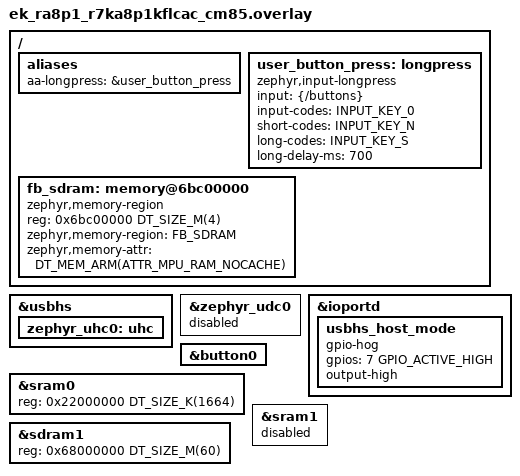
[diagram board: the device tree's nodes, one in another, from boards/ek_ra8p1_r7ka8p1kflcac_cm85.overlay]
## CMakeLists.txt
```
# Copyright The Zephyr Project Contributors
# SPDX-License-Identifier: Apache-2.0

cmake_minimum_required(VERSION 3.28.0)
find_package(Zephyr REQUIRED HINTS $ENV{ZEPHYR_BASE})
project(android_auto_headunit)

list(APPEND CMAKE_MODULE_PATH ${ZEPHYR_BASE}/modules/nanopb)
include(nanopb)

zephyr_nanopb_sources(app src/aa.proto)

if(CONFIG_SOC_SERIES_STM32N6X)
  zephyr_linker_sources(SECTIONS axisram1_check.ld)
endif()

# Both ESP32-P4 cores fetch through one flash cache, which the decoder's
# per-macroblock code would otherwise keep thrashing
if(CONFIG_SOC_SERIES_ESP32P4 AND CONFIG_SAMPLE_AA_HU_H264)
  zephyr_linker_sources(RAMFUNC_SECTION h264bsd_iram.ld)
endif()

# The Espressif linker scripts place the section in PSRAM themselves
if(CONFIG_MBEDTLS_HEAP_CUSTOM_SECTION AND NOT CONFIG_ESP_MBEDTLS_HEAP_ALLOC_EXT_RAM)
  zephyr_linker_sources(SECTIONS mbedtls_heap.ld)
endif()

target_sources(app PRIVATE
  src/aa_audio.c
  src/aa_control.c
  src/aa_frame.c
  src/aa_input.c
  src/aa_layout.c
  src/aa_mic.c
  src/aa_nav.c
  src/aa_play.c
  src/aa_scale.c
  src/aa_screen.c
  src/aa_sensor.c
  src/aa_session.c
  src/aa_tls.c
  src/aa_tof.c
  src/aa_video.c
  src/h264_ipcm_decode.c
  src/main.c
)

target_sources_ifdef(CONFIG_SAMPLE_AA_HU_TRANSPORT_TCP app PRIVATE src/aa_transport_tcp.c)
target_sources_ifdef(CONFIG_SAMPLE_AA_HU_TRANSPORT_NONE app PRIVATE src/aa_transport_none.c)
target_sources_ifdef(CONFIG_SAMPLE_AA_HU_DEMO_CLIP app PRIVATE src/aa_demo.c)
target_sources_ifdef(CONFIG_SAMPLE_AA_HU_SPLIT_SCREEN app PRIVATE src/aa_gui.c)

# The decoder is the h264bsd module, which the west manifest carries; only
# the glue that drives it belongs to the sample.
target_sources_ifdef(CONFIG_SAMPLE_AA_HU_H264 app PRIVATE src/aa_h264.c)

# ESP32-P4 PIE kernels, assembled with the compiler given to h264bsd for its own
if(H264BSD_PIE_CC)
  set(pie_obj ${CMAKE_CURRENT_BINARY_DIR}/aa_pack_pie.obj)
  add_custom_command(OUTPUT ${pie_obj}
    COMMAND ${H264BSD_PIE_CC} -march=rv32imafc_zicsr_zifencei_xesploop_xespv -mabi=ilp32f
            -c ${CMAKE_CURRENT_SOURCE_DIR}/src/aa_pack_pie.S -o ${pie_obj}.tmp
    COMMAND ${CMAKE_OBJCOPY} --remove-section .riscv.attributes ${pie_obj}.tmp ${pie_obj}
    DEPENDS src/aa_pack_pie.S)
  set_source_files_properties(${pie_obj} PROPERTIES EXTERNAL_OBJECT TRUE GENERATED TRUE)
  target_sources(app PRIVATE ${pie_obj})
  target_compile_definitions(app PRIVATE AA_HU_HAS_PIE)
endif()

if(CONFIG_SAMPLE_AA_HU_TRANSPORT_USB_HOST)
  target_sources(app PRIVATE src/aa_transport_usbh.c)
  # The host stack keeps its request and descriptor helpers private
  target_include_directories(app PRIVATE ${ZEPHYR_BASE}/subsys/usb/host)
endif()

if(CONFIG_SAMPLE_AA_HU_FB_DUMP)
  target_sources(app PRIVATE src/hu_fb_dump.c)
  target_sources(native_simulator INTERFACE src/hu_fb_dump_bottom.c)
endif()

# Embed the PEM credentials, NUL terminated by the including source file
set(gen_dir ${ZEPHYR_BINARY_DIR}/include/generated)
foreach(cred cert key)
  string(TOUPPER ${cred} cred_upper)
  set(cred_path "${CONFIG_SAMPLE_AA_HU_${cred_upper}_FILE}")
  if(NOT IS_ABSOLUTE "${cred_path}")
    set(cred_path "${CMAKE_CURRENT_SOURCE_DIR}/${cred_path}")
  endif()
  generate_inc_file_for_target(app ${cred_path} ${gen_dir}/hu_${cred}.pem.inc)
endforeach()
```

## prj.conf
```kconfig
CONFIG_LOG=y
CONFIG_MAIN_STACK_SIZE=4096

CONFIG_INPUT=y
CONFIG_DISPLAY=y

CONFIG_PSA_CRYPTO=y
CONFIG_MBEDTLS=y
CONFIG_MBEDTLS_ENABLE_HEAP=y
CONFIG_MBEDTLS_HEAP_SIZE=49152
# A phone negotiates an RSA key exchange and, on older builds, an AES-CBC
# cipher, so offer those alongside the ECDSA suite
CONFIG_MBEDTLS_CIPHERSUITE_TLS_ECDHE_ECDSA_WITH_AES_128_GCM_SHA256=y
CONFIG_MBEDTLS_CIPHERSUITE_TLS_ECDHE_RSA_WITH_AES_128_GCM_SHA256=y
CONFIG_MBEDTLS_CIPHERSUITE_TLS_ECDHE_RSA_WITH_AES_128_CBC_SHA256=y
CONFIG_MBEDTLS_SSL_IN_CONTENT_LEN=8192
CONFIG_MBEDTLS_SSL_OUT_CONTENT_LEN=16384
CONFIG_MBEDTLS_PEM_PARSE_C=y
CONFIG_MBEDTLS_ECP_NIST_OPTIM=y
CONFIG_ENTROPY_GENERATOR=y

CONFIG_NANOPB=y

# The decoder's reference pictures are large and this sample places them
# itself, in a bank chosen per board
CONFIG_H264BSD_MALLOC="aa_h264_malloc"
CONFIG_H264BSD_FREE="aa_h264_free"
```

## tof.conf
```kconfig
# Time-of-flight ranger standing in for a light sensor, on the serial boot
# target. Use with tof.overlay and the shield that carries the ranger:
#
#   west build -b stm32n6570_dk/stm32n657xx/sb -- \
#     -DSHIELD=st_b_cams_imx_mb1854 \
#     -DEXTRA_DTC_OVERLAY_FILE=tof.overlay -DEXTRA_CONF_FILE=tof.conf
#
# The driver carries an 86 KB firmware image that it uploads to the sensor.
# A serial boot image is loaded into the 511 KB of internal RAM and keeps its
# read-only data there too, so the head unit gives up the parts it can to make
# room for it.

CONFIG_SENSOR=y
CONFIG_SENSOR_ASYNC_API=y
CONFIG_SAMPLE_AA_HU_TOF_NIGHT=y

# The ranger sits on the bus the navigation display is wired to, so that goes,
# and the audio path goes with it to free the rest
CONFIG_CHARACTER_FRAMEBUFFER=n
CONFIG_I2S=n
CONFIG_AUDIO_CODEC=n
CONFIG_AUDIO_DMIC=n

# The receive pipe moves to the memory the decoder heap is in, which has room
# to spare, rather than being made smaller. The USB transfer pool keeps its
# size: halving it makes the TLS handshake fail with a send error, since the
# transport cannot get a buffer to write into.
CONFIG_SAMPLE_AA_HU_USBH_RX_PIPE_SECTION="AXISRAM3"
CONFIG_SAMPLE_AA_HU_H264_HEAP_SIZE=1810432
CONFIG_USBH_STACK_SIZE=3072
CONFIG_USBH_USB_DEVICE_HEAP=2048
CONFIG_INPUT_THREAD_STACK_SIZE=3072
```

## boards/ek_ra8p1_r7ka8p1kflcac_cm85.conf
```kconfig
# The head unit is the USB host and the phone is the device, which is what the
# SoC's high speed controller does here. The board overlay puts it on the USB-C
# connector; SW4-8 has to select USBHS for that connector rather than USBFS.
CONFIG_SAMPLE_AA_HU_TRANSPORT_USB_HOST=y
CONFIG_USB_HOST_STACK=y
CONFIG_UDC_DRIVER=n
CONFIG_UHC_XFER_COUNT=32
CONFIG_UHC_BUF_COUNT=32
CONFIG_UHC_BUF_POOL_SIZE=16384
CONFIG_USBH_STACK_SIZE=4096
CONFIG_USBH_USB_DEVICE_HEAP=4096

# The host mode pin is driven by a hog rather than by any driver
CONFIG_GPIO_HOGS=y

CONFIG_SAMPLE_AA_HU_H264=y

# Neither the reference pictures nor the framebuffer come close to fitting in
# the internal RAM, so both go to the 64 MB of SDRAM the board carries.
CONFIG_SAMPLE_AA_HU_BUFFERS_IN_EXT_RAM=y
CONFIG_SAMPLE_AA_HU_BUFFERS_SECTION="SDRAM"
CONFIG_SAMPLE_AA_HU_H264_HEAP_SECTION="SDRAM"

# What a real phone asks for: it sends TLS records of the full sixteen
# kilobytes and packs several of them into one frame, and its access units are
# far larger than the companion sample's.
CONFIG_MBEDTLS_SSL_IN_CONTENT_LEN=16384
CONFIG_MBEDTLS_HEAP_SIZE=98304
CONFIG_SAMPLE_AA_HU_RX_FRAME_SIZE=65600
CONFIG_SAMPLE_AA_HU_RX_MSG_SIZE=610000

# The receive thread runs the TLS record layer as well as the protocol, and
# builds messages that are large on a 64-bit-wide bus
CONFIG_SAMPLE_AA_HU_RX_STACK_SIZE=16384

# The decoder works out of the external RAM its pictures are too large for
# anywhere else, and reaching it uncached costs about five sixths of the frame
# rate. The framebuffer is flushed before the display controller reads it.
CONFIG_DCACHE=y
CONFIG_CACHE_MANAGEMENT=y

# The SoC forces the cache write-through by default, which leaves every store
# to the external RAM on the bus. Only the framebuffer is read by anything
# other than the core, and it is flushed before the panel is given it.
CONFIG_CPU_RA_DCACHE_WRITEBACK=y

# The pictures are split off from the rest of the decoder state so that the
# two can live in different memories.
CONFIG_H264BSD_PICTURE_MALLOC="aa_h264_picture_malloc"
CONFIG_H264BSD_PICTURE_FREE="aa_h264_picture_free"

# Without output reordering a phone's baseline stream needs two pictures, and
# two fit in the internal RAM once the second core's bank is taken in. Every
# read of a reference and every pass over the picture being built then costs a
# fraction of what it does in the external RAM. A stream that wants more falls
# back to the external heap rather than stopping.
CONFIG_SAMPLE_AA_HU_H264_HEAP_SECTION=".bss"
CONFIG_SAMPLE_AA_HU_H264_HEAP_SIZE=1155072
CONFIG_SAMPLE_AA_HU_H264_HEAP_FALLBACK=y

# Measured high water mark is 333 KB, and it moves a little with the stream
CONFIG_SAMPLE_AA_HU_H264_STATE_HEAP_SIZE=380928

# Make room: none of these is read often enough to earn internal RAM
CONFIG_MBEDTLS_HEAP_CUSTOM_SECTION=y
CONFIG_SAMPLE_AA_HU_TX_BUFFERS_SECTION="SDRAM"
CONFIG_SAMPLE_AA_HU_USBH_RX_PIPE_SECTION="SDRAM"

# The panel reports touches on its interrupt line, so it does not have to be
# polled. Touch events are forwarded from the input thread, which encrypts and
# writes them to USB.
CONFIG_INPUT_FT5336_INTERRUPT=y
CONFIG_INPUT_FT5336_MAX_TOUCH_POINTS=3
CONFIG_INPUT_THREAD_STACK_SIZE=4096
CONFIG_INPUT_QUEUE_MAX_MSGS=64
```

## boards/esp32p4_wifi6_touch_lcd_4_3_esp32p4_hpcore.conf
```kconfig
CONFIG_SAMPLE_AA_HU_TRANSPORT_USB_HOST=y
CONFIG_USB_HOST_STACK=y

# zephyr_udc0 and zephyr_uhc0 are the same controller on this SoC
CONFIG_UDC_DRIVER=n

CONFIG_UHC_XFER_COUNT=32
CONFIG_UHC_BUF_COUNT=32
CONFIG_UHC_BUF_POOL_SIZE=16384
CONFIG_USBH_STACK_SIZE=4096
CONFIG_USBH_USB_DEVICE_HEAP=4096

CONFIG_SAMPLE_AA_HU_H264=y

# The 480x800 panel scans in portrait. Turned a quarter turn it is exactly the
# 800x480 picture the phone sends, which then needs no scaling.
CONFIG_SAMPLE_AA_HU_ROTATE_90=y

# The sample scans its own two surfaces out of PSRAM, so the display driver
# needs none of its own
CONFIG_DISPLAY_ESP32_DSI_FB_NUM=0

# What a real phone asks for: it sends TLS records of the full sixteen
# kilobytes and packs several of them into one frame
CONFIG_MBEDTLS_SSL_IN_CONTENT_LEN=16384
CONFIG_MBEDTLS_HEAP_SIZE=98304
CONFIG_ESP_MBEDTLS_HEAP_ALLOC_EXT_RAM=y
CONFIG_SAMPLE_AA_HU_RX_FRAME_SIZE=65600
CONFIG_SAMPLE_AA_HU_RX_MSG_SIZE=610000
CONFIG_SAMPLE_AA_HU_RX_STACK_SIZE=16384

# The pictures go to PSRAM with the other large buffers. The rest of the
# decoder state is read far more often per byte and stays in internal RAM,
# which the decoder's hot code shares. It has held 338368 bytes at 800x480.
CONFIG_SAMPLE_AA_HU_H264_STATE_HEAP_SECTION=".bss"
CONFIG_SAMPLE_AA_HU_H264_STATE_HEAP_SIZE=360448

# Only the processor touches these, so they need not take internal RAM
CONFIG_SAMPLE_AA_HU_TX_BUFFERS_SECTION=".ext_ram.bss"
CONFIG_SAMPLE_AA_HU_USBH_RX_PIPE_SECTION=".ext_ram.bss"

# The GT911 INT line is not routed, so the driver polls it
CONFIG_INPUT_GT911_MAX_TOUCH_POINTS=3
CONFIG_INPUT_THREAD_STACK_SIZE=4096
CONFIG_INPUT_QUEUE_MAX_MSGS=64

# Touches are handled on the input thread, which defaults to the lowest
# application priority and is starved by the receive thread decoding video
CONFIG_INPUT_THREAD_PRIORITY_OVERRIDE=y
CONFIG_INPUT_THREAD_PRIORITY=4
CONFIG_INPUT_LOG_LEVEL_ERR=y

# H.264 decoding is limited by CPU time rather than code size
CONFIG_SPEED_OPTIMIZATIONS=y

# The pixel processing accelerator converts and turns the pictures
CONFIG_ESP32_PPA=y

# Every picture crosses PSRAM several times, and a longer cache line fetches
# it in longer bursts: 128 bytes reads a third faster than 64
CONFIG_ESP32_CACHE_L2_LINE_128B=y
CONFIG_SPIRAM_SPEED_250M=y

# The log thread overran its 768 byte default into the next stack with SMP
CONFIG_LOG_PROCESS_THREAD_STACK_SIZE=2048

# Both HP cores: pictures are composed on the second one, and the deblocking
# follows the decoder there a row of macroblocks behind
CONFIG_SMP=y
CONFIG_H264BSD_DEBLOCK_THREAD=y
# and packs the rows it is done with for the accelerator while they are cached
CONFIG_H264BSD_DEBLOCK_ROWS_HOOK="aa_h264_rows_ready"
```

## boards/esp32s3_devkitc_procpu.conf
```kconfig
CONFIG_SAMPLE_AA_HU_TRANSPORT_USB_HOST=y
CONFIG_USB_HOST_STACK=y

# zephyr_udc0 and zephyr_uhc0 are the same controller on this SoC
CONFIG_UDC_DRIVER=n

CONFIG_UHC_XFER_COUNT=32
CONFIG_UHC_BUF_COUNT=32
CONFIG_UHC_BUF_POOL_SIZE=16384
CONFIG_USBH_STACK_SIZE=4096
CONFIG_USBH_USB_DEVICE_HEAP=4096

CONFIG_SAMPLE_AA_HU_TX_CHUNK_SIZE=8192
CONFIG_MBEDTLS_SSL_OUT_CONTENT_LEN=8192
CONFIG_MBEDTLS_SSL_IN_CONTENT_LEN=8192
CONFIG_MBEDTLS_HEAP_SIZE=40960

# External RAM holds the framebuffer and a full I_PCM key frame from the
# companion accessory sample
CONFIG_ESP_SPIRAM=y
CONFIG_SPIRAM_MODE_QUAD=y
CONFIG_SAMPLE_AA_HU_RX_MSG_SIZE=610000
```

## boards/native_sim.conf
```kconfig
CONFIG_SAMPLE_AA_HU_TRANSPORT_TCP=y

CONFIG_NETWORKING=y
CONFIG_NET_IPV4=y
CONFIG_NET_IPV6=n
CONFIG_NET_SOCKETS=y
CONFIG_NET_SOCKETS_OFFLOAD=y
CONFIG_NET_DRIVERS=y
CONFIG_NET_NATIVE_OFFLOADED_SOCKETS=y
CONFIG_ETH_NATIVE_TAP=n

CONFIG_MBEDTLS_HEAP_SIZE=65536

# Hold a full I_PCM key frame from the companion accessory sample
CONFIG_SAMPLE_AA_HU_RX_MSG_SIZE=610000
```

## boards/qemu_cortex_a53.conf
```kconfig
# No phone can be reached from an emulator, so the head unit decodes the clip
# built into the image instead and everything after the decoder is unchanged.
CONFIG_SAMPLE_AA_HU_TRANSPORT_NONE=y
CONFIG_SAMPLE_AA_HU_H264=y
CONFIG_SAMPLE_AA_HU_DEMO_CLIP=y

# Say where each picture's time goes: the machine is emulated, so this is the
# one number that says whether the video keeps up
CONFIG_SAMPLE_AA_HU_VIDEO_PROFILE=y

# Nothing to report the light level to
CONFIG_SAMPLE_AA_HU_NIGHT_BUTTON=n

# The stream is one of the sample's own and needs one reference picture
CONFIG_SAMPLE_AA_HU_H264_HEAP_SIZE=2097152

# Sixty-four bit, where the sizes the sample carries for 32-bit boards are tight
CONFIG_MAIN_STACK_SIZE=8192
CONFIG_SAMPLE_AA_HU_GUI_STACK_SIZE=4096

# The surface, the decoder's arena and the reassembly buffer are each mapped in
# their own right, and the eight tables the architecture port starts with do
# not cover them
CONFIG_MAX_XLAT_TABLES=32
```

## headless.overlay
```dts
/*
 * Copyright The Zephyr Project Contributors
 * SPDX-License-Identifier: Apache-2.0
 */

/*
 * Decode without a window, for a machine that has no display to open one on.
 * CONFIG_SAMPLE_AA_HU_FB_DUMP writes the pictures to a file instead.
 */
/ {
	chosen {
		zephyr,display = &dummy_dc;
	};

	dummy_dc: dummy_dc {
		compatible = "zephyr,dummy-dc";
		height = <480>;
		width = <800>;
	};
};

&input_sdl_touch {
	status = "disabled";
};
```

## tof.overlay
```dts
/*
 * Copyright The Zephyr Project Contributors
 * SPDX-License-Identifier: Apache-2.0
 */

/*
 * Point the sample at the time-of-flight ranger of the B-CAMS-IMX-MB1854, so
 * that covering it puts the phone into night mode:
 *
 *   west build -b stm32n6570_dk/stm32n657xx/sb -- \
 *     -DSHIELD=st_b_cams_imx_mb1854 -DEXTRA_DTC_OVERLAY_FILE=tof.overlay
 *
 * The ranger sits on the camera connector's I2C controller, which is the one
 * the navigation display of this sample is wired to through the Arduino
 * header, and the shield drives it at 400 kHz where the display needs 100 kHz.
 * Only one of the two can be fitted, so the display goes.
 */

/ {
	aliases {
		aa-tof = &vl53l5cx;
	};
};

&nav_display {
	status = "disabled";
};
```

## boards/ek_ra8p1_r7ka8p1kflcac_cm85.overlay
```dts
/*
 * Copyright The Zephyr Project Contributors
 * SPDX-License-Identifier: Apache-2.0
 */

#include <zephyr/dt-bindings/input/input-event-codes.h>
#include <zephyr/dt-bindings/memory-attr/memory-attr-arm.h>

/*
 * The high speed controller drives the board's USB-C connector, which is where
 * the phone attaches. SW4-8 selects USBHS for that connector.
 */
&usbhs {
	status = "okay";

	zephyr_uhc0: uhc {
		status = "okay";
	};
};

/* One controller, one role: the board enables the device side by default */
&zephyr_udc0 {
	status = "disabled";
};

/*
 * The connector is a device port until PD07 is driven high, which is also what
 * turns on the five volts the phone draws: in host mode J7 is fed from U18,
 * good for two amps. The board leaves port D off entirely.
 */
&ioportd {
	status = "okay";

	usbhs_host_mode {
		gpio-hog;
		gpios = <7 GPIO_ACTIVE_HIGH>;
		output-high;
	};
};

/* The board leaves its buttons off, and the layout needs one */
&button0 {
	status = "okay";
};

/ {
	aliases {
		aa-longpress = &user_button_press;
	};

	/*
	 * Holding the button switches the display between the phone alone and
	 * the phone beside the head unit's own GUI; a tap switches night mode.
	 */
	user_button_press: longpress {
		compatible = "zephyr,input-longpress";
		input = <&{/buttons}>;
		input-codes = <INPUT_KEY_0>;
		short-codes = <INPUT_KEY_N>;
		long-codes = <INPUT_KEY_S>;
		long-delay-ms = <700>;
	};
};

/*
 * The second core is not started, so its RAM is free. The two banks are
 * contiguous, which makes them one 1664 KB bank the decoder's pictures fit in.
 */
&sram0 {
	reg = <0x22000000 DT_SIZE_K(1664)>;
};

&sram1 {
	status = "disabled";
};

/*
 * The display controller reads the surface for every line it draws, while the
 * processor writes it once per frame. Holding it in the data cache makes the
 * processor read each line back before overwriting it, and that traffic is
 * bandwidth the controller needs: it underruns and drops a band of the
 * picture. Give it the top of the external RAM, uncached.
 */
&sdram1 {
	reg = <0x68000000 DT_SIZE_M(60)>;
};

/ {
	fb_sdram: memory@6bc00000 {
		compatible = "zephyr,memory-region", "mmio-sram";
		reg = <0x6bc00000 DT_SIZE_M(4)>;
		zephyr,memory-region = "FB_SDRAM";
		zephyr,memory-attr = <DT_MEM_ARM(ATTR_MPU_RAM_NOCACHE)>;
	};
};
```

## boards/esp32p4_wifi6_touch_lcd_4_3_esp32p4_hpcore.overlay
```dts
/*
 * Copyright The Zephyr Project Contributors
 * SPDX-License-Identifier: Apache-2.0
 */

#include <zephyr/dt-bindings/input/input-event-codes.h>

/*
 * The high-speed OTG controller is the host the phone is attached to, on the
 * Type-C connector next to the USB to UART one. That connector presents itself
 * as a sink and takes its VBUS from outside rather than supplying it, so the
 * phone has to be reached through a powered hub or a VBUS injector.
 */
zephyr_uhc0: &usb_otg {
	status = "okay";
};

/*
 * The panel scans in portrait and the sample turns the picture a quarter turn
 * clockwise, so the touch screen reports positions in the same turned frame.
 */
&gt911 {
	inverted-x;
	swapped-x-y;
};

/* Converts the decoded pictures to RGB565 and turns them onto the panel */
&ppa {
	status = "okay";
};

/ {
	aliases {
		aa-longpress = &boot_button_press;
	};

	/*
	 * The BOOT button taps to switch the phone between its day and night
	 * themes, and held switches the display to split screen and back.
	 */
	boot_button_press: longpress {
		compatible = "zephyr,input-longpress";
		input = <&{/gpio_keys}>;
		input-codes = <INPUT_KEY_0>;
		short-codes = <INPUT_KEY_N>;
		long-codes = <INPUT_KEY_S>;
		long-delay-ms = <700>;
	};
};
```

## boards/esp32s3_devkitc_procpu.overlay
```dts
/*
 * Copyright The Zephyr Project Contributors
 * SPDX-License-Identifier: Apache-2.0
 */

#include <mem.h>

/*
 * The board has no display, so the decoded pictures go to a dummy one. This
 * target exists to bring up the USB host side against a real phone.
 */
/ {
	chosen {
		zephyr,display = &dummy_dc;
	};

	dummy_dc: dummy_dc {
		compatible = "zephyr,dummy-dc";
		height = <480>;
		width = <800>;
	};
};

/* Modules with 8 MB of PSRAM (N8R8) hold the framebuffer */
&psram0 {
	size = <DT_SIZE_M(8)>;
};
```

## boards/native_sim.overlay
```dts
/*
 * Copyright The Zephyr Project Contributors
 * SPDX-License-Identifier: Apache-2.0
 */

#include <zephyr/dt-bindings/display/panel.h>

/*
 * The board's SDL window is the head unit's panel: it shows the phone's
 * projected screen and its mouse drives the input channel as the touch screen.
 * Size it to the resolution the sample offers the phone, in the format the
 * decoder writes.
 */
&sdl_dc {
	pixel-format = <PANEL_PIXEL_FORMAT_RGB_565>;
	height = <480>;
	width = <800>;
};

/*
 * The board's file-backed audio: the phone's audio goes to the I2S TX device,
 * and the microphone the phone listens to reads from the DMIC device. Point
 * both at named pipes to hear and speak through the host's own sound system
 * (see the README); a plain file works for a recording.
 */
/ {
	aliases {
		aa-i2s-out = &i2s_tx0;
		aa-audio-codec = &audio_codec;
	};
};
```

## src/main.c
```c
/*
 * Copyright The Zephyr Project Contributors
 * SPDX-License-Identifier: Apache-2.0
 */

#include <zephyr/kernel.h>
#include <zephyr/logging/log.h>

#include "aa_demo.h"
#include "aa_session.h"

LOG_MODULE_REGISTER(aa_hu_main, CONFIG_SAMPLE_AA_HU_LOG_LEVEL);

int main(void)
{
	int ret;

	if (IS_ENABLED(CONFIG_SAMPLE_AA_HU_DEMO_CLIP)) {
		ret = aa_hu_demo_start();
	} else {
		ret = aa_hu_session_start();
	}

	if (ret != 0) {
		LOG_ERR("Head unit start failed (%d)", ret);
	}

	return 0;
}
```

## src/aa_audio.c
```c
/*
 * Copyright The Zephyr Project Contributors
 * SPDX-License-Identifier: Apache-2.0
 */

#include "aa_audio.h"

#include <zephyr/logging/log.h>

#include "src/aa.pb.h"
#include "aa_frame.h"
#include "aa_ids.h"
#include "aa_play.h"
#include "aa_session.h"

LOG_MODULE_REGISTER(aa_audio, CONFIG_SAMPLE_AA_HU_LOG_LEVEL);

/*
 * Audio channels. A phone expects a head unit to provide media, speech and
 * system audio sinks, and refuses to project without them. The sample has
 * nowhere to play the samples, so it sets the streams up and acknowledges the
 * media messages without decoding them.
 */

static int32_t sessions[ARRAY_SIZE(((struct aa_hu_session *)0)->audio_ch)];

/* The order service discovery offers the sinks in */
static const int32_t audio_types[] = {
	AA_AUDIO_TYPE_GUIDANCE,
	AA_AUDIO_TYPE_SYSTEM,
	AA_AUDIO_TYPE_MEDIA,
};
BUILD_ASSERT(ARRAY_SIZE(audio_types) == ARRAY_SIZE(sessions),
	     "one audio type per advertised channel");

static int channel_index(uint8_t channel)
{
	const struct aa_hu_session *s = aa_hu_session_get();

	for (size_t i = 0; i < ARRAY_SIZE(s->audio_ch); i++) {
		if (s->audio_ch[i] == channel) {
			return (int)i;
		}
	}

	return -1;
}

bool aa_audio_is_audio_channel(uint8_t channel)
{
	return channel_index(channel) >= 0;
}

static void send_setup_response(uint8_t channel)
{
	AVChannelSetupResponse rsp = AVChannelSetupResponse_init_zero;
	uint8_t buf[32];
	int n;

	rsp.has_media_status = true;
	rsp.media_status = AA_MEDIA_STATUS_OK;
	rsp.has_max_unacked = true;
	rsp.max_unacked = 1;
	rsp.configs_count = 1;
	rsp.configs[0] = 0;

	n = aa_pb_encode(buf, sizeof(buf), AVChannelSetupResponse_fields, &rsp);
	if (n >= 0) {
		(void)aa_msg_send(channel, false, AA_AV_SETUP_RESPONSE, buf, (size_t)n);
	}
}

static void send_media_ack(uint8_t channel, int idx)
{
	AVMediaAckIndication ack = AVMediaAckIndication_init_zero;
	uint8_t buf[16];
	int n;

	ack.has_session = true;
	ack.session = sessions[idx];
	ack.has_value = true;
	ack.value = 1;

	n = aa_pb_encode(buf, sizeof(buf), AVMediaAckIndication_fields, &ack);
	if (n >= 0) {
		(void)aa_msg_send(channel, false, AA_AV_MEDIA_ACK_INDICATION, buf, (size_t)n);
	}
}

void aa_audio_handle(uint8_t channel, uint16_t msg_id, const uint8_t *body, size_t len)
{
	int idx = channel_index(channel);

	if (idx < 0) {
		return;
	}

	switch (msg_id) {
	case AA_AV_SETUP_REQUEST:
		send_setup_response(channel);
		break;

	case AA_AV_START_INDICATION: {
		AVChannelStartIndication ind = AVChannelStartIndication_init_zero;

		if (aa_pb_decode(body, len, AVChannelStartIndication_fields, &ind) == 0) {
			sessions[idx] = ind.session;
			LOG_INF("Audio channel %u started, session %d", channel, ind.session);
		}
		break;
	}

	case AA_AV_STOP_INDICATION:
		aa_play_flush(audio_types[idx]);
		break;

	case AA_AV_MEDIA_WITH_TIMESTAMP_INDICATION:
	case AA_AV_MEDIA_INDICATION: {
		/* A timestamped message puts the time before the samples */
		size_t skip = (msg_id == AA_AV_MEDIA_WITH_TIMESTAMP_INDICATION) ? sizeof(uint64_t)
									       : 0U;

		/*
		 * Acknowledged first: the phone holds off until it is, and the
		 * samples are of no use late.
		 */
		send_media_ack(channel, idx);
		if (len > skip) {
			aa_play_submit(audio_types[idx], &body[skip], len - skip);
		}
		break;
	}

	default:
		LOG_DBG("Unhandled audio message 0x%04x on channel %u", msg_id, channel);
		break;
	}
}
```

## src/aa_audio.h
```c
/*
 * Copyright The Zephyr Project Contributors
 * SPDX-License-Identifier: Apache-2.0
 */

#ifndef SAMPLES_SUBSYS_USB_ANDROID_AUTO_HEADUNIT_SRC_AA_AUDIO_H_
#define SAMPLES_SUBSYS_USB_ANDROID_AUTO_HEADUNIT_SRC_AA_AUDIO_H_

#include <stdbool.h>
#include <stddef.h>
#include <stdint.h>

/** @brief Handle a message on one of the audio channels. */
void aa_audio_handle(uint8_t channel, uint16_t msg_id, const uint8_t *body, size_t len);

/** @brief True when the channel is one of the advertised audio channels. */
bool aa_audio_is_audio_channel(uint8_t channel);

#endif /* SAMPLES_SUBSYS_USB_ANDROID_AUTO_HEADUNIT_SRC_AA_AUDIO_H_ */
```

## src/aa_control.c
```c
/*
 * Copyright The Zephyr Project Contributors
 * SPDX-License-Identifier: Apache-2.0
 */

#include "aa_control.h"

#include <string.h>

#include <zephyr/kernel.h>
#include <zephyr/logging/log.h>
#include <zephyr/sys/byteorder.h>

#include "src/aa.pb.h"
#include "aa_frame.h"
#include "aa_ids.h"
#include "aa_session.h"
#include "aa_tls.h"
#include "aa_video.h"

LOG_MODULE_REGISTER(aa_control, CONFIG_SAMPLE_AA_HU_LOG_LEVEL);

/*
 * Control channel, head unit side: the head unit requests the protocol version,
 * initiates the TLS handshake, declares authentication complete and answers the
 * phone's service discovery with the channels it offers.
 */

#define AA_VIDEO_CHANNEL_ID 1U
#define AA_INPUT_CHANNEL_ID 2U
#define AA_SENSOR_CHANNEL_ID 3U
#define AA_GUIDANCE_AUDIO_CHANNEL_ID 4U
#define AA_SYSTEM_AUDIO_CHANNEL_ID   5U
#define AA_MEDIA_AUDIO_CHANNEL_ID    6U
#define AA_MIC_CHANNEL_ID            7U
#define AA_NAV_CHANNEL_ID            8U

#if defined(CONFIG_SAMPLE_AA_HU_VIDEO_1280X720)
#define AA_OFFERED_RESOLUTION AA_VIDEO_RESOLUTION_1280x720
#else
#define AA_OFFERED_RESOLUTION AA_VIDEO_RESOLUTION_800x480
#endif

#if defined(CONFIG_SAMPLE_AA_HU_VIDEO_60FPS)
#define AA_OFFERED_FPS AA_VIDEO_FPS_60
#else
#define AA_OFFERED_FPS AA_VIDEO_FPS_30
#endif

int aa_control_send_version_request(void)
{
	uint8_t body[4];

	sys_put_be16(AA_PROTO_MAJOR, &body[0]);
	sys_put_be16(CONFIG_SAMPLE_AA_HU_PROTO_MINOR, &body[2]);

	return aa_msg_send(AA_CHANNEL_CONTROL, false, AA_CTRL_VERSION_REQUEST, body, sizeof(body));
}

static int send_service_discovery_response(void)
{
	ServiceDiscoveryResponse rsp = ServiceDiscoveryResponse_init_zero;
	struct aa_hu_session *s = aa_hu_session_get();
	ChannelDescriptor *video = &rsp.channels[0];
	ChannelDescriptor *input = &rsp.channels[1];
	ChannelDescriptor *sensor = &rsp.channels[2];
	ChannelDescriptor *mic = &rsp.channels[3];
	ChannelDescriptor *nav = &rsp.channels[4];
	VideoConfig *cfg = &video->av_channel.video_configs[0];
	static const struct {
		uint8_t channel_id;
		int32_t audio_type;
		uint32_t sample_rate;
		uint32_t channel_count;
	} audio[] = {
		{AA_GUIDANCE_AUDIO_CHANNEL_ID, AA_AUDIO_TYPE_GUIDANCE, 16000U, 1U},
		{AA_SYSTEM_AUDIO_CHANNEL_ID, AA_AUDIO_TYPE_SYSTEM, 16000U, 1U},
		{AA_MEDIA_AUDIO_CHANNEL_ID, AA_AUDIO_TYPE_MEDIA, 48000U, 2U},
	};
	uint8_t buf[512];
	int len;

	rsp.channels_count = 5U + ARRAY_SIZE(audio);

	video->has_channel_id = true;
	video->channel_id = AA_VIDEO_CHANNEL_ID;
	video->has_av_channel = true;
	video->av_channel.has_stream_type = true;
	video->av_channel.stream_type = AA_STREAM_TYPE_VIDEO;
	video->av_channel.video_configs_count = 1;
	cfg->has_video_resolution = true;
	cfg->video_resolution = AA_OFFERED_RESOLUTION;
	cfg->has_video_fps = true;
	cfg->video_fps = AA_OFFERED_FPS;
	cfg->has_dpi = true;
	cfg->dpi = 160;

	input->has_channel_id = true;
	input->channel_id = AA_INPUT_CHANNEL_ID;
	input->has_input_channel = true;
	input->input_channel.has_touch_screen_config = true;
	input->input_channel.touch_screen_config.has_width = true;
	input->input_channel.touch_screen_config.width = CONFIG_SAMPLE_AA_HU_VIDEO_WIDTH;
	input->input_channel.touch_screen_config.has_height = true;
	input->input_channel.touch_screen_config.height = CONFIG_SAMPLE_AA_HU_VIDEO_HEIGHT;

	/*
	 * A phone refuses to project without a driving status source, so a
	 * sensor channel is advertised even though the values are static.
	 */
	sensor->has_channel_id = true;
	sensor->channel_id = AA_SENSOR_CHANNEL_ID;
	sensor->has_sensor_channel = true;
	sensor->sensor_channel.sensors_count = 4;
	sensor->sensor_channel.sensors[0].has_type = true;
	sensor->sensor_channel.sensors[0].type = AA_SENSOR_TYPE_DRIVING_STATUS;
	sensor->sensor_channel.sensors[1].has_type = true;
	sensor->sensor_channel.sensors[1].type = AA_SENSOR_TYPE_NIGHT_DATA;
	sensor->sensor_channel.sensors[2].has_type = true;
	sensor->sensor_channel.sensors[2].type = AA_SENSOR_TYPE_PARKING_BRAKE;
	sensor->sensor_channel.sensors[3].has_type = true;
	sensor->sensor_channel.sensors[3].type = AA_SENSOR_TYPE_GEAR;

	strncpy(rsp.head_unit_name, CONFIG_SAMPLE_AA_HU_NAME, sizeof(rsp.head_unit_name) - 1U);
	rsp.has_head_unit_name = true;
	strncpy(rsp.car_model, "Zephyr", sizeof(rsp.car_model) - 1U);
	rsp.has_car_model = true;
	strncpy(rsp.car_year, "2026", sizeof(rsp.car_year) - 1U);
	rsp.has_car_year = true;
	strncpy(rsp.car_serial, "0000000000000001", sizeof(rsp.car_serial));
	rsp.car_serial[sizeof(rsp.car_serial) - 1U] = '\0';
	rsp.has_car_serial = true;
	rsp.has_driver_position = true;
	rsp.driver_position = AA_DRIVER_POSITION_LEFT;
	strncpy(rsp.headunit_manufacturer, "Zephyr Project",
		sizeof(rsp.headunit_manufacturer) - 1U);
	rsp.has_headunit_manufacturer = true;
	strncpy(rsp.headunit_model, "Android Auto sample", sizeof(rsp.headunit_model) - 1U);
	rsp.has_headunit_model = true;
	strncpy(rsp.sw_build, "1", sizeof(rsp.sw_build) - 1U);
	rsp.has_sw_build = true;
	strncpy(rsp.sw_version, "1.0", sizeof(rsp.sw_version) - 1U);
	rsp.has_sw_version = true;
	rsp.has_can_play_native_media_during_vr = true;
	rsp.can_play_native_media_during_vr = false;

	/*
	 * A phone expects somewhere to play media, navigation prompts and
	 * system sounds, and treats a head unit without them as incompatible.
	 */
	for (size_t i = 0; i < ARRAY_SIZE(audio); i++) {
		ChannelDescriptor *ch = &rsp.channels[5U + i];
		AudioConfig *acfg = &ch->av_channel.audio_configs[0];

		ch->has_channel_id = true;
		ch->channel_id = audio[i].channel_id;
		ch->has_av_channel = true;
		ch->av_channel.has_stream_type = true;
		ch->av_channel.stream_type = AA_STREAM_TYPE_AUDIO;
		ch->av_channel.has_audio_type = true;
		ch->av_channel.audio_type = audio[i].audio_type;
		ch->av_channel.audio_configs_count = 1;
		acfg->has_sample_rate = true;
		acfg->sample_rate = audio[i].sample_rate;
		acfg->has_bit_depth = true;
		acfg->bit_depth = 16U;
		acfg->has_channel_count = true;
		acfg->channel_count = audio[i].channel_count;

		s->audio_ch[i] = audio[i].channel_id;
	}

	/* A microphone source, which a phone requires for voice input */
	mic->has_channel_id = true;
	mic->channel_id = AA_MIC_CHANNEL_ID;
	mic->has_av_input_channel = true;
	mic->av_input_channel.has_stream_type = true;
	mic->av_input_channel.stream_type = AA_STREAM_TYPE_AUDIO;
	mic->av_input_channel.has_audio_config = true;
	mic->av_input_channel.audio_config.has_sample_rate = true;
	mic->av_input_channel.audio_config.sample_rate = 16000U;
	mic->av_input_channel.audio_config.has_bit_depth = true;
	mic->av_input_channel.audio_config.bit_depth = 16U;
	mic->av_input_channel.audio_config.has_channel_count = true;
	mic->av_input_channel.audio_config.channel_count = 1U;

	/*
	 * A navigation status sink. The turn is asked for as an enumeration
	 * rather than a picture: what it drives is a few lines of text.
	 */
	nav->has_channel_id = true;
	nav->channel_id = AA_NAV_CHANNEL_ID;
	nav->has_navigation_status_service = true;
	nav->navigation_status_service.has_minimum_interval_ms = true;
	nav->navigation_status_service.minimum_interval_ms = 1000;
	nav->navigation_status_service.has_type = true;
	nav->navigation_status_service.type = AA_NAV_CLUSTER_ENUM;

	s->nav_ch = AA_NAV_CHANNEL_ID;
	s->video_ch = AA_VIDEO_CHANNEL_ID;
	s->input_ch = AA_INPUT_CHANNEL_ID;
	s->mic_ch = AA_MIC_CHANNEL_ID;
	s->sensor_ch = AA_SENSOR_CHANNEL_ID;

	len = aa_pb_encode(buf, sizeof(buf), ServiceDiscoveryResponse_fields, &rsp);
	if (len < 0) {
		return len;
	}

	LOG_INF("Offering video, input, sensor, audio, microphone and navigation channels");

	return aa_msg_send(AA_CHANNEL_CONTROL, false, AA_CTRL_SERVICE_DISCOVERY_RESPONSE, buf,
			   (size_t)len);
}

static void continue_handshake(const uint8_t *body, size_t len)
{
	int ret = aa_tls_handshake_input(body, len);

	if (ret == -EAGAIN) {
		return;
	}
	if (ret != 0) {
		aa_hu_session_abort("TLS handshake failed");
		return;
	}

	/* Handshake done: tell the phone authentication is complete */
	AuthCompleteIndication ind = AuthCompleteIndication_init_zero;
	uint8_t buf[8];
	int n;

	ind.has_status = true;
	ind.status = AA_STATUS_OK;
	n = aa_pb_encode(buf, sizeof(buf), AuthCompleteIndication_fields, &ind);
	if (n < 0 || aa_msg_send(AA_CHANNEL_CONTROL, false, AA_CTRL_AUTH_COMPLETE, buf,
				 (size_t)n) != 0) {
		aa_hu_session_abort("auth complete failed");
		return;
	}

	aa_frame_set_encrypted(true);
	aa_hu_session_set_state(AA_HU_WAIT_SERVICE_DISCOVERY);
}

void aa_control_handle(uint16_t msg_id, const uint8_t *body, size_t len)
{
	struct aa_hu_session *s = aa_hu_session_get();

	switch (msg_id) {
	case AA_CTRL_VERSION_RESPONSE:
		if (len >= 4U) {
			s->md_major = sys_get_be16(&body[0]);
			s->md_minor = sys_get_be16(&body[2]);
		}
		if (len >= 6U && sys_get_be16(&body[4]) != 0U) {
			aa_hu_session_abort("phone reported a version mismatch");
			return;
		}
		LOG_INF("Phone protocol version %u.%u", s->md_major, s->md_minor);
		if (aa_tls_handshake_start() == -EIO) {
			aa_hu_session_abort("cannot start the TLS handshake");
			return;
		}
		aa_hu_session_set_state(AA_HU_HANDSHAKE);
		break;

	case AA_CTRL_SSL_HANDSHAKE:
		continue_handshake(body, len);
		break;

	case AA_CTRL_SERVICE_DISCOVERY_REQUEST: {
		ServiceDiscoveryRequest req = ServiceDiscoveryRequest_init_zero;

		if (aa_pb_decode(body, len, ServiceDiscoveryRequest_fields, &req) == 0) {
			LOG_INF("Phone \"%s\" (%s)", req.has_device_name ? req.device_name : "?",
				req.has_label_text ? req.label_text : "?");
		}
		if (send_service_discovery_response() != 0) {
			aa_hu_session_abort("service discovery response failed");
			return;
		}
		aa_hu_session_set_state(AA_HU_RUNNING);
		break;
	}

	case AA_CTRL_NAVIGATION_FOCUS_REQUEST: {
		NavigationFocusRequest req = NavigationFocusRequest_init_zero;
		NavigationFocusResponse rsp = NavigationFocusResponse_init_zero;
		uint8_t buf[16];
		int n;

		(void)aa_pb_decode(body, len, NavigationFocusRequest_fields, &req);

		/* Mirror the requested type back to grant navigation focus */
		rsp.has_type = true;
		rsp.type = req.has_type ? req.type : 2U;

		n = aa_pb_encode(buf, sizeof(buf), NavigationFocusResponse_fields, &rsp);
		if (n >= 0) {
			(void)aa_msg_send(AA_CHANNEL_CONTROL, false,
					  AA_CTRL_NAVIGATION_FOCUS_RESPONSE, buf, (size_t)n);
		}
		break;
	}

	case AA_CTRL_AUDIO_FOCUS_REQUEST: {
		AudioFocusRequest req = AudioFocusRequest_init_zero;
		AudioFocusResponse rsp = AudioFocusResponse_init_zero;
		uint8_t buf[16];
		int n;

		if (aa_pb_decode(body, len, AudioFocusRequest_fields, &req) != 0) {
			break;
		}

		/*
		 * Nothing here plays audio, so focus is granted immediately and
		 * only a release is reported back as a loss.
		 */
		rsp.has_focus_state = true;
		rsp.focus_state = (req.audio_focus_type == AA_AUDIO_FOCUS_RELEASE)
					  ? AA_AUDIO_FOCUS_STATE_LOSS
					  : AA_AUDIO_FOCUS_STATE_GAIN;

		LOG_INF("Audio focus request %d, reporting state %d", req.audio_focus_type,
			rsp.focus_state);

		n = aa_pb_encode(buf, sizeof(buf), AudioFocusResponse_fields, &rsp);
		if (n >= 0) {
			(void)aa_msg_send(AA_CHANNEL_CONTROL, false, AA_CTRL_AUDIO_FOCUS_RESPONSE,
					  buf, (size_t)n);
		}
		break;
	}

	case AA_CTRL_PING_REQUEST:
		(void)aa_msg_send(AA_CHANNEL_CONTROL, false, AA_CTRL_PING_RESPONSE, body, len);
		break;

	case AA_CTRL_PING_RESPONSE:
	case AA_CTRL_NAVIGATION_FOCUS_RESPONSE:
		break;

	case AA_CTRL_SHUTDOWN_REQUEST:
		LOG_INF("Phone requested shutdown");
		(void)aa_msg_send(AA_CHANNEL_CONTROL, false, AA_CTRL_SHUTDOWN_RESPONSE, NULL, 0U);
		aa_hu_session_abort("shutdown");
		break;

	default:
		LOG_WRN("Unhandled control message 0x%04x", msg_id);
		break;
	}
}

void aa_control_channel_open(uint8_t channel, const uint8_t *body, size_t len)
{
	ChannelOpenRequest req = ChannelOpenRequest_init_zero;
	ChannelOpenResponse rsp = ChannelOpenResponse_init_zero;
	uint8_t buf[8];
	int n;

	(void)aa_pb_decode(body, len, ChannelOpenRequest_fields, &req);
	LOG_INF("Channel %u open request (priority %d)", channel, req.priority);

	rsp.has_status = true;
	rsp.status = AA_STATUS_OK;
	n = aa_pb_encode(buf, sizeof(buf), ChannelOpenResponse_fields, &rsp);
	if (n >= 0) {
		(void)aa_msg_send(channel, true, AA_CTRL_CHANNEL_OPEN_RESPONSE, buf, (size_t)n);
	}
}
```

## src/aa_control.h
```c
/*
 * Copyright The Zephyr Project Contributors
 * SPDX-License-Identifier: Apache-2.0
 */

#ifndef SAMPLES_SUBSYS_USB_ANDROID_AUTO_HEADUNIT_SRC_AA_CONTROL_H_
#define SAMPLES_SUBSYS_USB_ANDROID_AUTO_HEADUNIT_SRC_AA_CONTROL_H_

#include <stddef.h>
#include <stdint.h>

/** @brief Send the initial version request to the phone. */
int aa_control_send_version_request(void);

/** @brief Handle a message received on the control channel. */
void aa_control_handle(uint16_t msg_id, const uint8_t *body, size_t len);

/** @brief Handle a channel open request received on a data channel. */
void aa_control_channel_open(uint8_t channel, const uint8_t *body, size_t len);

#endif /* SAMPLES_SUBSYS_USB_ANDROID_AUTO_HEADUNIT_SRC_AA_CONTROL_H_ */
```

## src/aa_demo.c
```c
/*
 * Copyright The Zephyr Project Contributors
 * SPDX-License-Identifier: Apache-2.0
 */

#include "aa_demo.h"

#include <stdbool.h>
#include <stddef.h>
#include <stdint.h>
#include <string.h>

#include <zephyr/kernel.h>
#include <zephyr/logging/log.h>

#include "aa_demo_clip.h"
#include "aa_h264.h"
#include "aa_input.h"
#include "aa_video.h"

LOG_MODULE_REGISTER(aa_demo, CONFIG_SAMPLE_AA_HU_LOG_LEVEL);

/*
 * A phone's video channel, without the phone. The clip in aa_demo_clip.h is an
 * Annex B elementary stream built into the image, and this hands it to the
 * decoder a picture at a time on a thread of its own, which is what the
 * receive thread does with the pictures a phone sends. Everything after the
 * decoder - the scaling, the layout and the head unit's own GUI - is the same
 * code either way, so the display shows what a phone would make it show.
 *
 * The clip starts on an IDR picture and holds no other, so playing it again
 * from the start needs nothing of the decoder.
 *
 * A picture is copied out of the clip before it is decoded. The decoder is
 * given a buffer it may rewrite - it takes the bytes that keep a payload from
 * looking like a start code back out of it - and the clip is in read only
 * memory, and would not survive the second time round if it were not.
 */

#define FRAME_PERIOD_MS (1000U / AA_DEMO_CLIP_FPS)
#define CLIP_SIZE       sizeof(aa_demo_clip)

static K_THREAD_STACK_DEFINE(clip_stack, CONFIG_SAMPLE_AA_HU_DEMO_CLIP_STACK_SIZE);
static struct k_thread clip_thread_data;
static uint8_t picture[AA_DEMO_CLIP_MAX_AU];

/* Annex B separates NAL units by three or four bytes, the last of them one */
static bool start_code(size_t at, size_t *len)
{
	if ((at + 3U) > CLIP_SIZE || aa_demo_clip[at] != 0U || aa_demo_clip[at + 1U] != 0U) {
		return false;
	}

	if (aa_demo_clip[at + 2U] == 1U) {
		*len = 3U;
		return true;
	}

	if ((at + 4U) <= CLIP_SIZE && aa_demo_clip[at + 2U] == 0U && aa_demo_clip[at + 3U] == 1U) {
		*len = 4U;
		return true;
	}

	return false;
}

/*
 * How much of the clip from @p off belongs to one picture. The encoder is told
 * to code a picture as a single slice, so the access unit ends with the first
 * coded slice in it and the parameter sets ahead of a key frame travel with
 * the picture they describe.
 *
 * A start code cannot appear inside a NAL unit - the encoder breaks up any
 * byte sequence that would look like one - so scanning for it needs no notion
 * of where the payload ends.
 */
static size_t picture_length(size_t off)
{
	size_t at = off;
	size_t len;

	while (at < CLIP_SIZE) {
		uint8_t type;

		if (!start_code(at, &len)) {
			at++;
			continue;
		}

		type = aa_demo_clip[at + len] & 0x1FU;
		at += len + 1U;

		/* 1 and 5 are the coded slice of a picture and of a key frame */
		if (type != 1U && type != 5U) {
			continue;
		}

		while (at < CLIP_SIZE && !start_code(at, &len)) {
			at++;
		}

		return at - off;
	}

	return CLIP_SIZE - off;
}

static void report_rate(uint32_t *shown, int64_t *since)
{
	int64_t now = k_uptime_get();
	uint32_t ms = (uint32_t)(now - *since);

	if (ms < 2000U) {
		return;
	}

	LOG_INF("Clip: %u.%u fps", (*shown * 1000U) / ms, ((*shown * 10000U) / ms) % 10U);
	*shown = 0U;
	*since = now;
}

static void clip_thread(void *p1, void *p2, void *p3)
{
	int64_t due = k_uptime_get();
	int64_t since = due;
	uint32_t shown = 0U;
	size_t off = 0U;

	ARG_UNUSED(p1);
	ARG_UNUSED(p2);
	ARG_UNUSED(p3);

	while (true) {
		size_t len = picture_length(off);
		size_t take = MIN(len, sizeof(picture));
		int64_t now;

		memcpy(picture, &aa_demo_clip[off], take);
		if (aa_h264_decode_au(picture, take) > 0) {
			shown++;
		}

		off += len;
		if (off >= CLIP_SIZE) {
			off = 0U;
		}

		report_rate(&shown, &since);

		/*
		 * Keep to the rate the clip was encoded at where there is time
		 * to spare, and to whatever the decoder manages where there is
		 * not, rather than trying to catch up on what it has missed.
		 *
		 * Give the processor up either way. This thread runs at the
		 * priority the receive thread would, which is above the GUI and
		 * above logging, and a decoder that cannot hold the frame rate
		 * would otherwise leave neither of them a moment to run in.
		 */
		due += FRAME_PERIOD_MS;
		now = k_uptime_get();
		if (due < now) {
			due = now;
		}

		k_sleep(K_MSEC(MAX(due - now, 1)));
	}
}

int aa_hu_demo_start(void)
{
	int ret = aa_video_init();

	if (ret != 0) {
		return ret;
	}

	/*
	 * The touch screen still belongs to the display it is on, so take it
	 * even though there is no phone to forward to: a touch is mapped back
	 * to the picture it landed on either way, and the channel simply never
	 * opens.
	 */
	ret = aa_input_init();
	if (ret != 0) {
		return ret;
	}

	k_thread_create(&clip_thread_data, clip_stack, K_THREAD_STACK_SIZEOF(clip_stack),
			clip_thread, NULL, NULL, NULL, CONFIG_SAMPLE_AA_HU_RX_THREAD_PRIORITY, 0,
			K_FOREVER);
	k_thread_name_set(&clip_thread_data, "aa_hu_clip");
	aa_h264_pin(&clip_thread_data);
	k_thread_start(&clip_thread_data);

	LOG_INF("Android Auto head unit ready (playing the built in clip, %ux%u)",
		AA_DEMO_CLIP_WIDTH, AA_DEMO_CLIP_HEIGHT);

	return 0;
}
```

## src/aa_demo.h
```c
/*
 * Copyright The Zephyr Project Contributors
 * SPDX-License-Identifier: Apache-2.0
 */

#ifndef SAMPLES_SUBSYS_USB_ANDROID_AUTO_HEADUNIT_SRC_AA_DEMO_H_
#define SAMPLES_SUBSYS_USB_ANDROID_AUTO_HEADUNIT_SRC_AA_DEMO_H_

#include <errno.h>

#ifdef CONFIG_SAMPLE_AA_HU_DEMO_CLIP

/**
 * @brief Bring up the display and play the clip built into the image.
 *
 * Takes the place of aa_hu_session_start() where no phone can be attached.
 *
 * @retval 0 Success.
 * @retval -ENODEV The display is not ready.
 * @retval -ENOMEM The decoder or the GUI could not be allocated.
 */
int aa_hu_demo_start(void);

#else

static inline int aa_hu_demo_start(void)
{
	return -ENOTSUP;
}

#endif /* CONFIG_SAMPLE_AA_HU_DEMO_CLIP */

#endif /* SAMPLES_SUBSYS_USB_ANDROID_AUTO_HEADUNIT_SRC_AA_DEMO_H_ */
```

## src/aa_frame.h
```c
/*
 * Copyright The Zephyr Project Contributors
 * SPDX-License-Identifier: Apache-2.0
 */

#ifndef SAMPLES_SUBSYS_USB_ANDROID_AUTO_SRC_AA_FRAME_H_
#define SAMPLES_SUBSYS_USB_ANDROID_AUTO_SRC_AA_FRAME_H_

#include <stdbool.h>
#include <stddef.h>
#include <stdint.h>

#include <zephyr/kernel.h>

/*
 * Messenger: turns messages into frames on the transport byte stream and back.
 *
 * Frame layout: channel (u8), flags (u8), payload length (u16 BE), total
 * message length (u32 BE, only in the first fragment of a fragmented message),
 * payload. A message payload starts with the u16 BE message id. Once the
 * session is authenticated every payload is one TLS record.
 */

/** A frame received from the head unit; payload points into the RX buffer. */
struct aa_frame_rx {
	uint8_t channel;
	uint8_t flags;
	uint16_t len;
	uint32_t total;
	uint8_t *payload;
};

/** @brief Initialize the messenger. */
int aa_frame_init(void);

/** @brief Forget any partially sent message and switch encryption off. */
void aa_frame_reset(void);

/** @brief Enable encryption of every message from now on (after AUTH_COMPLETE). */
void aa_frame_set_encrypted(bool on);

/** @brief Serialize access to the TLS context, the TX buffers and the transport. */
void aa_frame_lock(void);
void aa_frame_unlock(void);

/**
 * @brief Send one TLS record. Called by the TLS layer with the lock held.
 *
 * Before the session is encrypted the record is a handshake record and goes
 * out as an SSL_HANDSHAKE control message; afterwards it is the payload of the
 * frame currently being assembled.
 */
int aa_frame_tx_record(const uint8_t *record, size_t len);

/**
 * @brief Send a small message in a single frame.
 *
 * @param channel Channel id.
 * @param control true to set the control message flag.
 * @param msg_id Message id.
 * @param body Message body (protobuf or raw), may be NULL when len is 0.
 * @param len Body length.
 *
 * @retval 0 Success.
 * @retval -EMSGSIZE The body does not fit one frame.
 * @return Negative errno from the transport.
 */
int aa_msg_send(uint8_t channel, bool control, uint16_t msg_id, const uint8_t *body, size_t len);

/**
 * @brief Start a message whose body is streamed in fragments.
 *
 * @param channel Channel id.
 * @param msg_id Message id.
 * @param body_len Exact body length that will be written.
 */
int aa_msg_begin(uint8_t channel, uint16_t msg_id, size_t body_len);

/** @brief Append body bytes to the message started with aa_msg_begin(). */
int aa_msg_write(const uint8_t *data, size_t len);

/** @brief Flush the last fragment of the streamed message. */
int aa_msg_end(void);

/** @brief Drop a streamed message after an error. */
void aa_msg_abort(void);

/**
 * @brief Receive one frame.
 *
 * @param frame Filled with the frame; the payload is valid until the next call.
 * @param timeout Timeout for the first byte, the rest of the frame waits forever.
 *
 * @retval 0 Success.
 * @retval -ETIMEDOUT No frame started within the timeout.
 * @retval -ENOTCONN The link is gone.
 * @retval -EMSGSIZE The frame is larger than the RX buffer.
 */
int aa_frame_recv(struct aa_frame_rx *frame, k_timeout_t timeout);

#endif /* SAMPLES_SUBSYS_USB_ANDROID_AUTO_SRC_AA_FRAME_H_ */
```

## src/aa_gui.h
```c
/*
 * Copyright The Zephyr Project Contributors
 * SPDX-License-Identifier: Apache-2.0
 */

#ifndef SAMPLES_SUBSYS_USB_ANDROID_AUTO_HEADUNIT_SRC_AA_GUI_H_
#define SAMPLES_SUBSYS_USB_ANDROID_AUTO_HEADUNIT_SRC_AA_GUI_H_

#include <stdbool.h>
#include <stdint.h>

#include <zephyr/toolchain.h>

#ifdef CONFIG_SAMPLE_AA_HU_SPLIT_SCREEN

/**
 * @brief Start the head unit's own GUI.
 *
 * @retval 0 Success.
 * @retval -ENOMEM The GUI could not be built.
 */
int aa_gui_init(void);

/**
 * @brief Copy the GUI into a packed YUYV display buffer.
 *
 * Only what has changed since this buffer was last written is converted,
 * unless the layout has moved the GUI since, in which case all of it is.
 *
 * @param dst   Start of the surface.
 * @param pitch Surface width in pixels.
 * @param idx   Which of the display buffers @p dst is.
 */
void aa_gui_apply_yuyv(uint8_t *dst, uint16_t pitch, unsigned int idx);

/** @brief Copy the GUI into an RGB565 display buffer. */
void aa_gui_apply_rgb565(uint16_t *dst, uint16_t pitch, unsigned int idx);

/** @brief Copy the GUI into an ARGB8888 display buffer. */
void aa_gui_apply_argb8888(uint32_t *dst, uint16_t pitch, unsigned int idx);

/** @brief Whether any display buffer is missing pixels the GUI has drawn. */
bool aa_gui_dirty(void);

#else /* CONFIG_SAMPLE_AA_HU_SPLIT_SCREEN */

static inline int aa_gui_init(void)
{
	return 0;
}

static inline void aa_gui_apply_yuyv(uint8_t *dst, uint16_t pitch, unsigned int idx)
{
	ARG_UNUSED(dst);
	ARG_UNUSED(pitch);
	ARG_UNUSED(idx);
}

static inline void aa_gui_apply_rgb565(uint16_t *dst, uint16_t pitch, unsigned int idx)
{
	ARG_UNUSED(dst);
	ARG_UNUSED(pitch);
	ARG_UNUSED(idx);
}

static inline bool aa_gui_dirty(void)
{
	return false;
}

#endif /* CONFIG_SAMPLE_AA_HU_SPLIT_SCREEN */

#endif /* SAMPLES_SUBSYS_USB_ANDROID_AUTO_HEADUNIT_SRC_AA_GUI_H_ */
```
